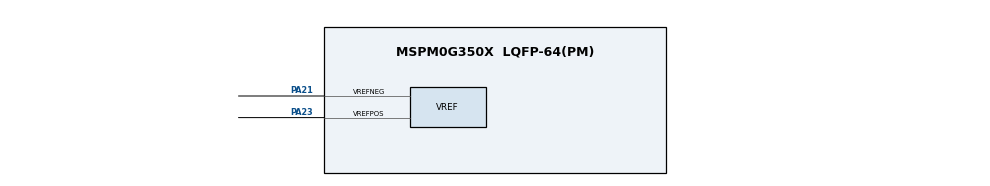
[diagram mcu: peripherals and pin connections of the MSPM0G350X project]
/**
 * @cliArgs --device "MSPM0G350X" --part "Default" --package "LQFP-64(PM)" --product "mspm0_sdk@2.10.00.04"
 * @versions {"tool":"1.26.2+4477"}
 */

/**
 * Import the modules used in this configuration.
 */
const DAC12  = scripting.addModule("/ti/driverlib/DAC12");
const GPIO   = scripting.addModule("/ti/driverlib/GPIO", {}, false);
const GPIO1  = GPIO.addInstance();
const GPIO2  = GPIO.addInstance();
const SYSCTL = scripting.addModule("/ti/driverlib/SYSCTL");
const VREF   = scripting.addModule("/ti/driverlib/VREF");

/**
 * Write custom configuration values to the imported modules.
 */
const gate8  = system.clockTree["MFPCLKGATE"];
gate8.enable = true;

DAC12.dacOutputPinEn     = true;
DAC12.dacAmplifier       = "ON";
DAC12.dacPosVREF         = "VEREFP";
DAC12.dacNegVREF         = "VEREFN";
DAC12.OutPinConfig.$name = "ti_driverlib_gpio_GPIOPinGeneric1";

const Board = scripting.addModule("/ti/driverlib/Board", {}, false);

GPIO1.$name                          = "BRIDGE_LASER";
GPIO1.associatedPins[0].$name        = "LASER";
GPIO1.associatedPins[0].assignedPort = "PORTA";
GPIO1.associatedPins[0].assignedPin  = "8";

GPIO2.$name                          = "BRIDGE_DUMMY";
GPIO2.associatedPins[0].$name        = "DUMMY";
GPIO2.associatedPins[0].assignedPort = "PORTA";
GPIO2.associatedPins[0].assignedPin  = "22";
GPIO2.associatedPins[0].initialValue = "SET";

SYSCTL.MFPCLKEn              = true;
SYSCTL.forceDefaultClkConfig = true;
SYSCTL.clockTreeEn           = true;

VREF.basicVrefPins                 = "VREF+-";
VREF.basicIntVolt                  = "DL_VREF_BUFCONFIG_OUTPUT_2_5V";
VREF.checkVREFReady                = true;
VREF.advClockConfigEnable          = true;
VREF.advClkSrc                     = "DL_VREF_CLOCK_BUSCLK";
VREF.vrefPosPinConfig.$name        = "ti_driverlib_gpio_GPIOPinGeneric0";
VREF.peripheral.$assign            = "VREF";
VREF.peripheral.vrefPosPin.$assign = "PA23";
VREF.peripheral.vrefNegPin.$assign = "PA21";
VREF.vrefNegPinConfig.$name        = "ti_driverlib_gpio_GPIOPinGeneric2";

/**
 * Pinmux solution for unlocked pins/peripherals. This ensures that minor changes to the automatic solver in a future
 * version of the tool will not impact the pinmux you originally saw.  These lines can be completely deleted in order to
 * re-solve from scratch.
 */
DAC12.peripheral.$suggestSolution            = "DAC0";
DAC12.peripheral.OutPin.$suggestSolution     = "PA15";
Board.peripheral.$suggestSolution            = "DEBUGSS";
Board.peripheral.swclkPin.$suggestSolution   = "PA20";
Board.peripheral.swdioPin.$suggestSolution   = "PA19";
GPIO1.associatedPins[0].pin.$suggestSolution = "PA8";
GPIO2.associatedPins[0].pin.$suggestSolution = "PA22";
